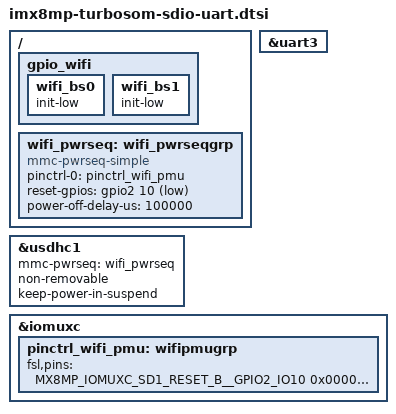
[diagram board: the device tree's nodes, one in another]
// SPDX-License-Identifier: (GPL-2.0+ OR MIT)
/*
 * Copyright 2021 Laird Connectivity
 */

/ {
	gpio_wifi {
		status = "okay";

		wifi_bs0 {
			init-low;
		};

		wifi_bs1 {
			init-low;
		};
	};

	wifi_pwrseq: wifi_pwrseqgrp {
		pinctrl-names = "default";
		pinctrl-0 = <&pinctrl_wifi_pmu>;

		compatible = "mmc-pwrseq-simple";
		reset-gpios = <&gpio2 10 GPIO_ACTIVE_LOW>;
		power-off-delay-us = <100000>;
	};
};

&uart3 { /* BT */
	status = "okay";
};

&usdhc1 {
	status = "okay";

	mmc-pwrseq = <&wifi_pwrseq>;

	non-removable;
	keep-power-in-suspend;
	//max-frequency = <100000000>;
};

&iomuxc {
	pinctrl_wifi_pmu: wifipmugrp {
		fsl,pins = <
			MX8MP_IOMUXC_SD1_RESET_B__GPIO2_IO10       0x00000006
		>;
	};
};
